# ATSAMC21N17A register map
Registers are 32-bit, access not given, no defined reset value unless marked. A register's access mark holds for its fields unless they carry their own. Addresses are absolute; registers are grouped by the start of their names; [hi:lo] are bit positions; {n}, {i} and the like mark numbered series; 'fields as' and 'values as' point back to an identical list.

## CAN1
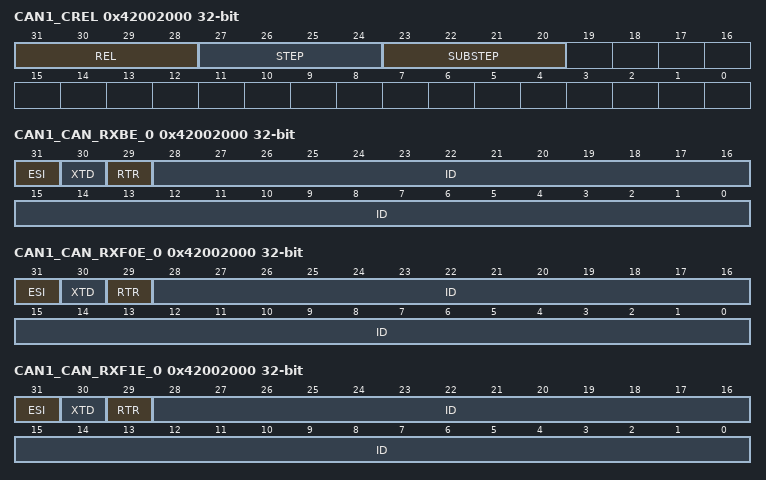
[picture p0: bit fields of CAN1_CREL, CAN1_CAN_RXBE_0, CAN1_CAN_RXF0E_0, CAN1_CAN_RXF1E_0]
0x42002000 CAN1_CREL — Core Release
  [31:28] REL, [27:24] STEP, [23:20] SUBSTEP
0x42002000 CAN1_CAN_RXBE_0 — Rx Buffer Element 0
  [31] ESI, [30] XTD, [29] RTR, [28:0] ID
0x42002000 CAN1_CAN_RXF0E_0 — Rx FIFO 0 Element 0
  [31] ESI, [30] XTD, [29] RTR, [28:0] ID
0x42002000 CAN1_CAN_RXF1E_0 — Rx FIFO 1 Element 0
  [31] ESI, [30] XTD, [29] RTR, [28:0] ID
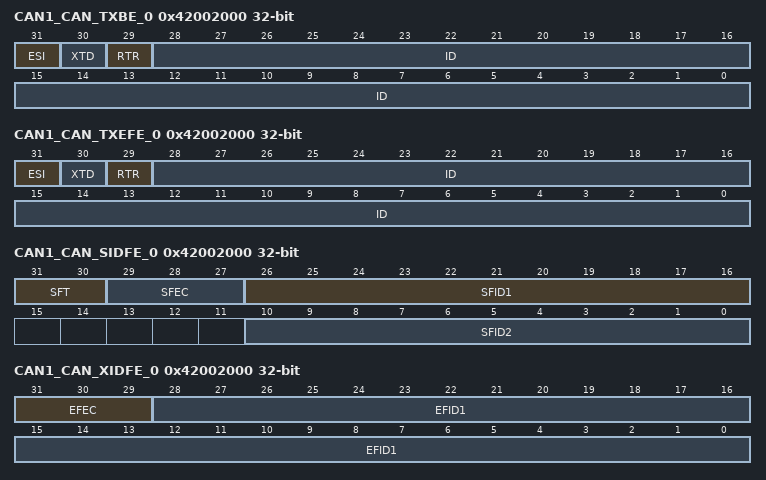
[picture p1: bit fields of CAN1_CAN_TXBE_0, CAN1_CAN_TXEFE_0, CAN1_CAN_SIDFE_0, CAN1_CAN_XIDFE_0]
0x42002000 CAN1_CAN_TXBE_0 — Tx Buffer Element 0
  [31] ESI, [30] XTD, [29] RTR, [28:0] ID
0x42002000 CAN1_CAN_TXEFE_0 — Tx Event FIFO Element 0
  [31] ESI, [30] XTD, [29] RTR, [28:0] ID
0x42002000 CAN1_CAN_SIDFE_0 — Standard Message ID Filter Element 0
  [31:30] SFT, [29:27] SFEC, [26:16] SFID1, [10:0] SFID2
0x42002000 CAN1_CAN_XIDFE_0 — Extended Message ID Filter Element 0
  [31:29] EFEC, [28:0] EFID1
0x42002004 CAN1_ENDN — Endian
  [31:0] ETV
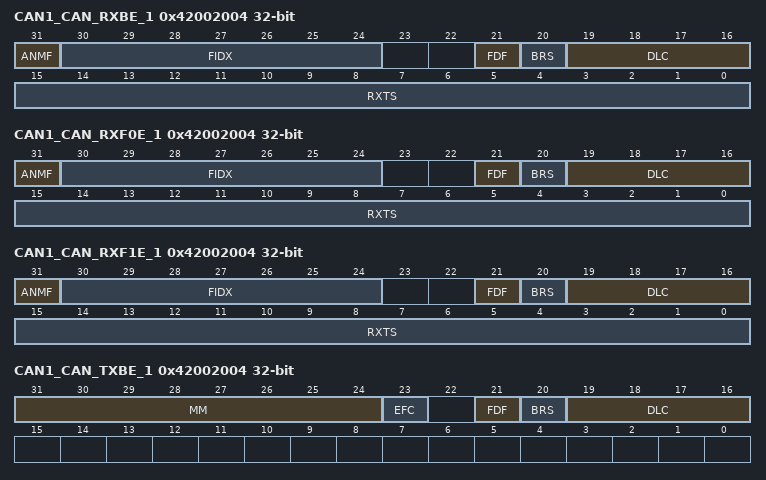
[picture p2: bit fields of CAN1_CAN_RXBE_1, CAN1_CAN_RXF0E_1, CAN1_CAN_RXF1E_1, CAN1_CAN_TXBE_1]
0x42002004 CAN1_CAN_RXBE_1 — Rx Buffer Element 1
  [31] ANMF, [30:24] FIDX, [21] FDF, [20] BRS, [19:16] DLC, [15:0] RXTS
0x42002004 CAN1_CAN_RXF0E_1 — Rx FIFO 0 Element 1
  fields as CAN1_CAN_RXBE_1
0x42002004 CAN1_CAN_RXF1E_1 — Rx FIFO 1 Element 1
  fields as CAN1_CAN_RXBE_1
0x42002004 CAN1_CAN_TXBE_1 — Tx Buffer Element 1
  [31:24] MM, [23] EFC, [21] FDF, [20] BRS, [19:16] DLC
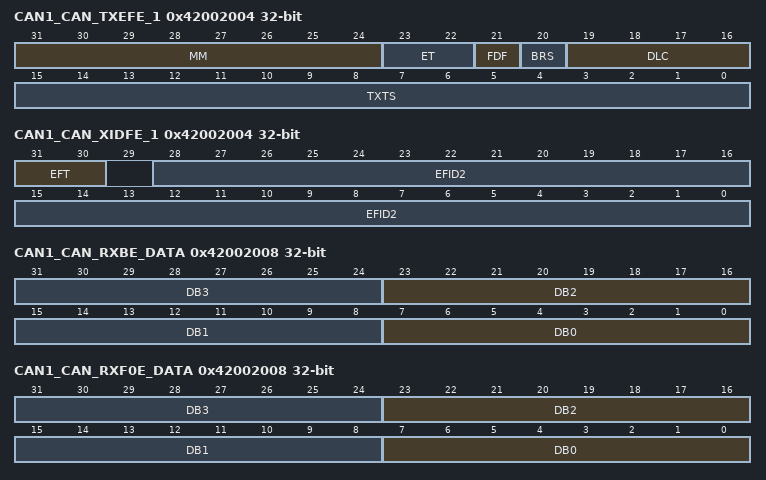
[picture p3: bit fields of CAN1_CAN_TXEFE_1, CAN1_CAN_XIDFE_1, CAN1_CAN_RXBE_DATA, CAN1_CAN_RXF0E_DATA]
0x42002004 CAN1_CAN_TXEFE_1 — Tx Event FIFO Element 1
  [31:24] MM, [23:22] ET, [21] FDF, [20] BRS, [19:16] DLC, [15:0] TXTS
0x42002004 CAN1_CAN_XIDFE_1 — Extended Message ID Filter Element 1
  [31:30] EFT, [28:0] EFID2
0x42002008 CAN1_MRCFG — Message RAM Configuration
  [1:0] QOS
0x42002008 CAN1_CAN_RXBE_DATA — Rx Buffer Element Data
  [8n+7:8n] DB{n} (n=0..3)
0x42002008 CAN1_CAN_RXF0E_DATA — Rx FIFO 0 Element Data
  [8n+7:8n] DB{n} (n=0..3)
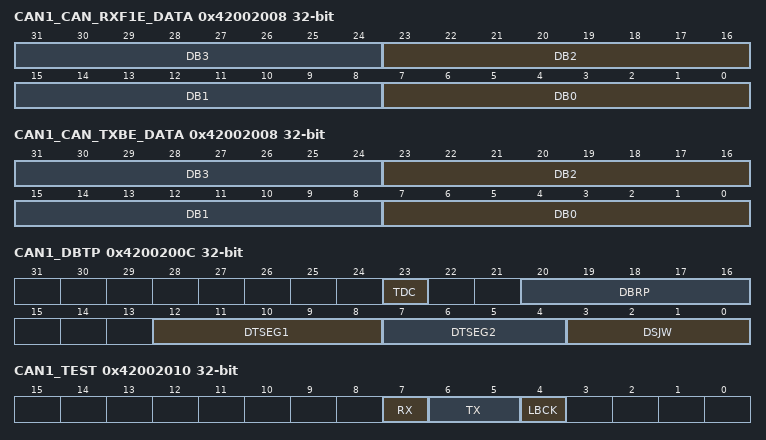
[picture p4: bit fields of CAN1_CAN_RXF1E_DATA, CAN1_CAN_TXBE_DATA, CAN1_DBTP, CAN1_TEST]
0x42002008 CAN1_CAN_RXF1E_DATA — Rx FIFO 1 Element Data
  [8n+7:8n] DB{n} (n=0..3)
0x42002008 CAN1_CAN_TXBE_DATA — Tx Buffer Element Data
  [8n+7:8n] DB{n} (n=0..3)
0x4200200C CAN1_DBTP — Fast Bit Timing and Prescaler
  [23] TDC, [20:16] DBRP, [12:8] DTSEG1, [7:4] DTSEG2, [3:0] DSJW
0x42002010 CAN1_TEST — Test
  [7] RX, [6:5] TX, [4] LBCK
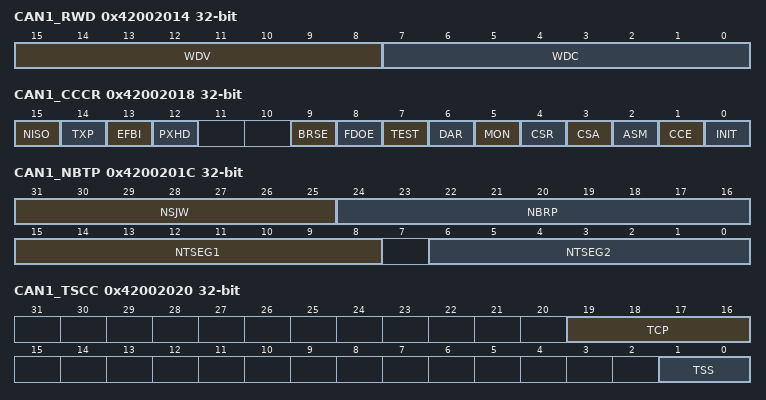
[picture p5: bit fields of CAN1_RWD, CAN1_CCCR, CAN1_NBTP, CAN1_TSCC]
0x42002014 CAN1_RWD — RAM Watchdog
  [15:8] WDV, [7:0] WDC
0x42002018 CAN1_CCCR — CC Control
  [15] NISO, [14] TXP, [13] EFBI, [12] PXHD, [9] BRSE, [8] FDOE, [7] TEST, [6] DAR, [5] MON, [4] CSR, [3] CSA, [2] ASM, [1] CCE, [0] INIT
0x4200201C CAN1_NBTP — Nominal Bit Timing and Prescaler
  [31:25] NSJW, [24:16] NBRP, [15:8] NTSEG1, [6:0] NTSEG2
0x42002020 CAN1_TSCC — Timestamp Counter Configuration
  [19:16] TCP, [1:0] TSS
0x42002024 CAN1_TSCV — Timestamp Counter Value
  [15:0] TSC
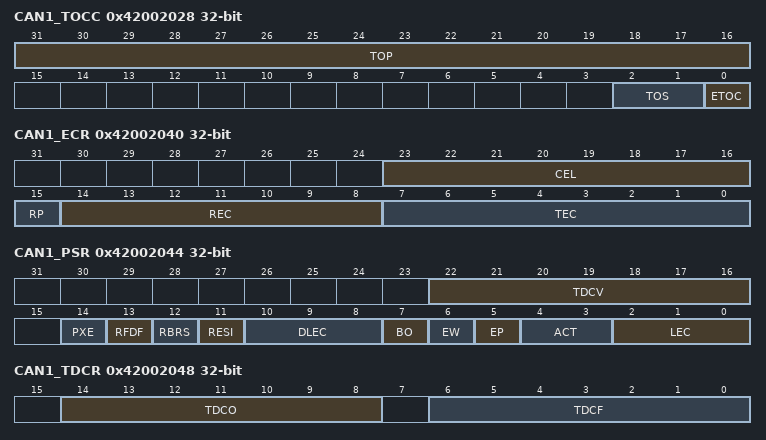
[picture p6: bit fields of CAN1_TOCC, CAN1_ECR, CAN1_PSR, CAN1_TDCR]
0x42002028 CAN1_TOCC — Timeout Counter Configuration
  [31:16] TOP, [2:1] TOS, [0] ETOC
0x4200202C CAN1_TOCV — Timeout Counter Value
  [15:0] TOC
0x42002040 CAN1_ECR — Error Counter
  [23:16] CEL, [15] RP, [14:8] REC, [7:0] TEC
0x42002044 CAN1_PSR — Protocol Status
  [22:16] TDCV, [14] PXE, [13] RFDF, [12] RBRS, [11] RESI, [10:8] DLEC, [7] BO, [6] EW, [5] EP, [4:3] ACT, [2:0] LEC
0x42002048 CAN1_TDCR — Extended ID Filter Configuration
  [14:8] TDCO, [6:0] TDCF
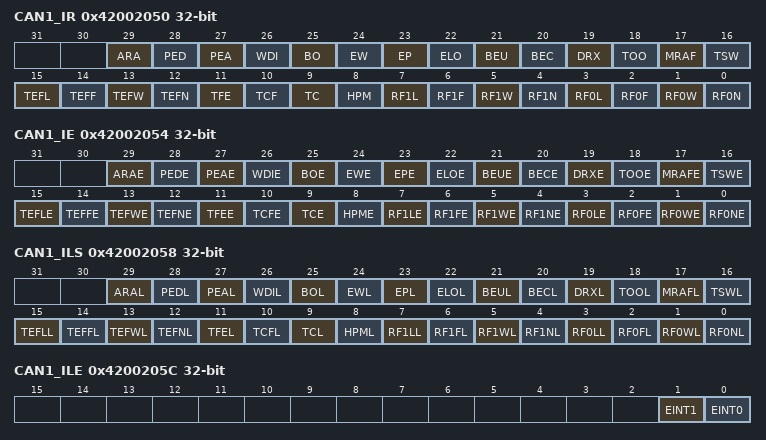
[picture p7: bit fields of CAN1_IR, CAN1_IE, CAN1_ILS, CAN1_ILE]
0x42002050 CAN1_IR — Interrupt
  [29] ARA, [28] PED, [27] PEA, [26] WDI, [25] BO, [24] EW, [23] EP, [22] ELO, [21] BEU, [20] BEC, [19] DRX, [18] TOO, [17] MRAF, [16] TSW, [15] TEFL, [14] TEFF, [13] TEFW, [12] TEFN, [11] TFE, [10] TCF, [9] TC, [8] HPM, [7] RF1L, [6] RF1F, [5] RF1W, [4] RF1N, [3] RF0L, [2] RF0F, [1] RF0W, [0] RF0N
0x42002054 CAN1_IE — Interrupt Enable
  [29] ARAE, [28] PEDE, [27] PEAE, [26] WDIE, [25] BOE, [24] EWE, [23] EPE, [22] ELOE, [21] BEUE, [20] BECE, [19] DRXE, [18] TOOE, [17] MRAFE, [16] TSWE, [15] TEFLE, [14] TEFFE, [13] TEFWE, [12] TEFNE, [11] TFEE, [10] TCFE, [9] TCE, [8] HPME, [7] RF1LE, [6] RF1FE, [5] RF1WE, [4] RF1NE, [3] RF0LE, [2] RF0FE, [1] RF0WE, [0] RF0NE
0x42002058 CAN1_ILS — Interrupt Line Select
  [29] ARAL, [28] PEDL, [27] PEAL, [26] WDIL, [25] BOL, [24] EWL, [23] EPL, [22] ELOL, [21] BEUL, [20] BECL, [19] DRXL, [18] TOOL, [17] MRAFL, [16] TSWL, [15] TEFLL, [14] TEFFL, [13] TEFWL, [12] TEFNL, [11] TFEL, [10] TCFL, [9] TCL, [8] HPML, [7] RF1LL, [6] RF1FL, [5] RF1WL, [4] RF1NL, [3] RF0LL, [2] RF0FL, [1] RF0WL, [0] RF0NL
0x4200205C CAN1_ILE — Interrupt Line Enable
  [1] EINT1, [0] EINT0
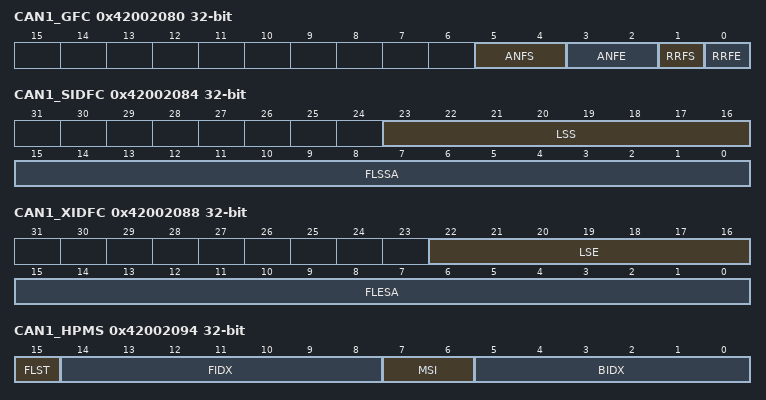
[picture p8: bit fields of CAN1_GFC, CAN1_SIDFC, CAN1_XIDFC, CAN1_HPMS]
0x42002080 CAN1_GFC — Global Filter Configuration
  [5:4] ANFS, [3:2] ANFE, [1] RRFS, [0] RRFE
0x42002084 CAN1_SIDFC — Standard ID Filter Configuration
  [23:16] LSS, [15:0] FLSSA
0x42002088 CAN1_XIDFC — Extended ID Filter Configuration
  [22:16] LSE, [15:0] FLESA
0x42002090 CAN1_XIDAM — Extended ID AND Mask
  [28:0] EIDM
0x42002094 CAN1_HPMS — High Priority Message Status
  [15] FLST, [14:8] FIDX, [7:6] MSI, [5:0] BIDX
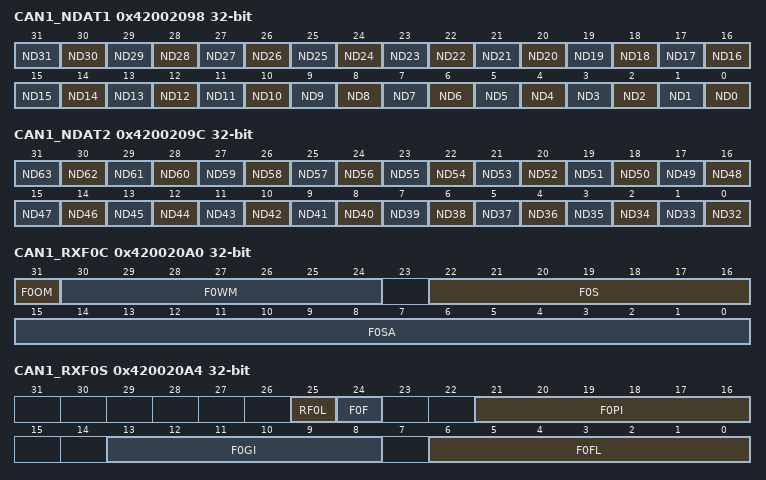
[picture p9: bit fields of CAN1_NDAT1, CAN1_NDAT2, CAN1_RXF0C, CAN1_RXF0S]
0x42002098 CAN1_NDAT1 — New Data 1
  [n] ND{n} (n=0..31)
0x4200209C CAN1_NDAT2 — New Data 2
  [n-32] ND{n} (n=32..63)
0x420020A0 CAN1_RXF0C — Rx FIFO 0 Configuration
  [31] F0OM, [30:24] F0WM, [22:16] F0S, [15:0] F0SA
0x420020A4 CAN1_RXF0S — Rx FIFO 0 Status
  [25] RF0L, [24] F0F, [21:16] F0PI, [13:8] F0GI, [6:0] F0FL
0x420020A8 CAN1_RXF0A — Rx FIFO 0 Acknowledge
  [5:0] F0AI
0x420020AC CAN1_RXBC — Rx Buffer Configuration
  [15:0] RBSA
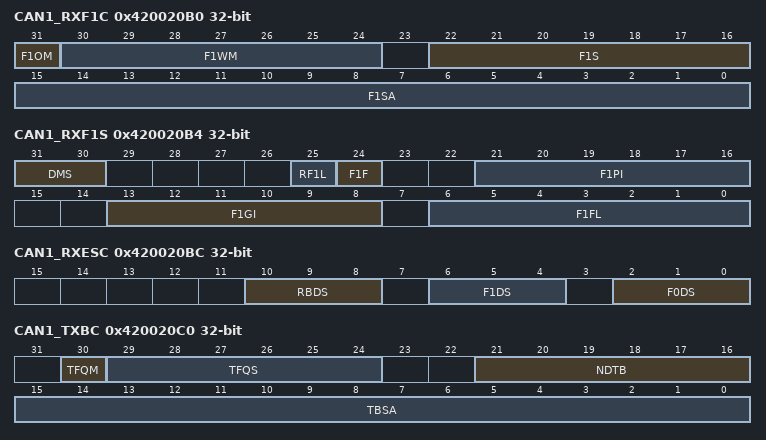
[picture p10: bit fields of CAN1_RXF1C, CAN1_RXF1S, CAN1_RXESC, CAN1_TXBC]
0x420020B0 CAN1_RXF1C — Rx FIFO 1 Configuration
  [31] F1OM, [30:24] F1WM, [22:16] F1S, [15:0] F1SA
0x420020B4 CAN1_RXF1S — Rx FIFO 1 Status
  [31:30] DMS, [25] RF1L, [24] F1F, [21:16] F1PI, [13:8] F1GI, [6:0] F1FL
0x420020B8 CAN1_RXF1A — Rx FIFO 1 Acknowledge
  [5:0] F1AI
0x420020BC CAN1_RXESC — Rx Buffer / FIFO Element Size Configuration
  [10:8] RBDS, [6:4] F1DS, [2:0] F0DS
0x420020C0 CAN1_TXBC — Tx Buffer Configuration
  [30] TFQM, [29:24] TFQS, [21:16] NDTB, [15:0] TBSA
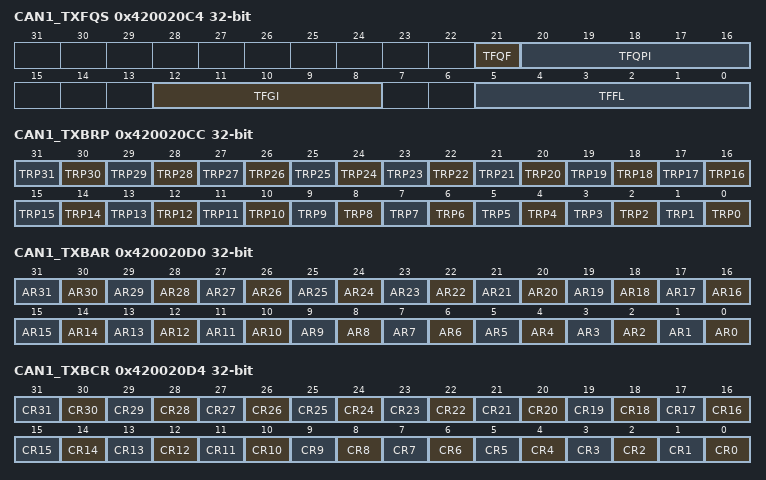
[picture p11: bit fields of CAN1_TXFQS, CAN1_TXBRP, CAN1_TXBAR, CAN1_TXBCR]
0x420020C4 CAN1_TXFQS — Tx FIFO / Queue Status
  [21] TFQF, [20:16] TFQPI, [12:8] TFGI, [5:0] TFFL
0x420020C8 CAN1_TXESC — Tx Buffer Element Size Configuration
  [2:0] TBDS
0x420020CC CAN1_TXBRP — Tx Buffer Request Pending
  [n] TRP{n} (n=0..31)
0x420020D0 CAN1_TXBAR — Tx Buffer Add Request
  [n] AR{n} (n=0..31)
0x420020D4 CAN1_TXBCR — Tx Buffer Cancellation Request
  [n] CR{n} (n=0..31)
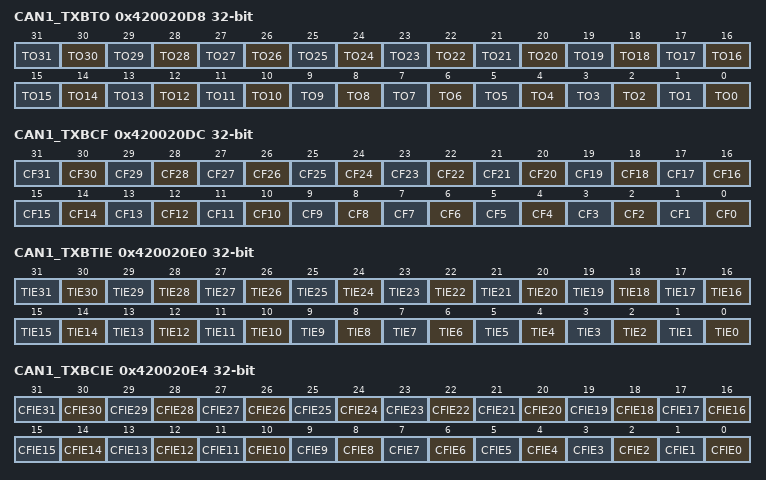
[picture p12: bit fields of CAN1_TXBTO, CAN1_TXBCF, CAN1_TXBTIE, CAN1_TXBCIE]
0x420020D8 CAN1_TXBTO — Tx Buffer Transmission Occurred
  [n] TO{n} (n=0..31)
0x420020DC CAN1_TXBCF — Tx Buffer Cancellation Finished
  [n] CF{n} (n=0..31)
0x420020E0 CAN1_TXBTIE — Tx Buffer Transmission Interrupt Enable
  [n] TIE{n} (n=0..31)
0x420020E4 CAN1_TXBCIE — Tx Buffer Cancellation Finished Interrupt Enable
  [n] CFIE{n} (n=0..31)
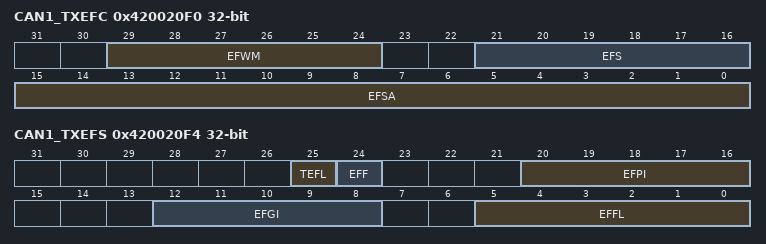
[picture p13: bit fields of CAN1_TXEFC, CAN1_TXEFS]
0x420020F0 CAN1_TXEFC — Tx Event FIFO Configuration
  [29:24] EFWM, [21:16] EFS, [15:0] EFSA
0x420020F4 CAN1_TXEFS — Tx Event FIFO Status
  [25] TEFL, [24] EFF, [20:16] EFPI, [12:8] EFGI, [5:0] EFFL
0x420020F8 CAN1_TXEFA — Tx Event FIFO Acknowledge
  [4:0] EFAI
